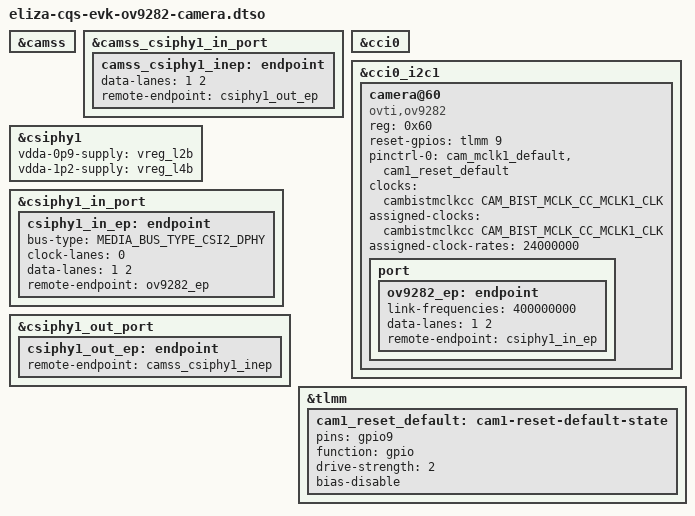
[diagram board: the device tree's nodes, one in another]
// SPDX-License-Identifier: BSD-3-Clause
/*
 * Copyright (c) Qualcomm Technologies, Inc. and/or its subsidiaries.
 */

/dts-v1/;
/plugin/;

#include <dt-bindings/clock/qcom,eliza-cambistmclkcc.h>
#include <dt-bindings/gpio/gpio.h>
#include <dt-bindings/media/video-interfaces.h>

&camss {
	status = "okay";
};

&camss_csiphy1_in_port {
	camss_csiphy1_inep: endpoint {
		data-lanes = <1 2>;
		remote-endpoint = <&csiphy1_out_ep>;
	};
};

&cci0 {
	status = "okay";
};

&cci0_i2c1 {
	#address-cells = <1>;
	#size-cells = <0>;

	camera@60 {
		compatible = "ovti,ov9282";
		reg = <0x60>;

		/* Reset is active-low, but driver applies inverted reset logic */
		reset-gpios = <&tlmm 9 GPIO_ACTIVE_HIGH>;
		pinctrl-0 = <&cam_mclk1_default &cam1_reset_default>;
		pinctrl-names = "default";

		clocks = <&cambistmclkcc CAM_BIST_MCLK_CC_MCLK1_CLK>;
		assigned-clocks = <&cambistmclkcc CAM_BIST_MCLK_CC_MCLK1_CLK>;
		assigned-clock-rates = <24000000>;

		port {
			ov9282_ep: endpoint {
				link-frequencies = /bits/ 64 <400000000>;
				data-lanes = <1 2>;
				remote-endpoint = <&csiphy1_in_ep>;
			};
		};
	};
};

&csiphy1 {
	vdda-0p9-supply = <&vreg_l2b>;
	vdda-1p2-supply = <&vreg_l4b>;

	status = "okay";
};

&csiphy1_in_port {
	csiphy1_in_ep: endpoint {
		bus-type = <MEDIA_BUS_TYPE_CSI2_DPHY>;
		clock-lanes = <0>;
		data-lanes = <1 2>;
		remote-endpoint = <&ov9282_ep>;
	};
};

&csiphy1_out_port {
	csiphy1_out_ep: endpoint {
		remote-endpoint = <&camss_csiphy1_inep>;
	};
};

&tlmm {
	cam1_reset_default: cam1-reset-default-state {
		pins = "gpio9";
		function = "gpio";
		drive-strength = <2>;
		bias-disable;
	};
};
